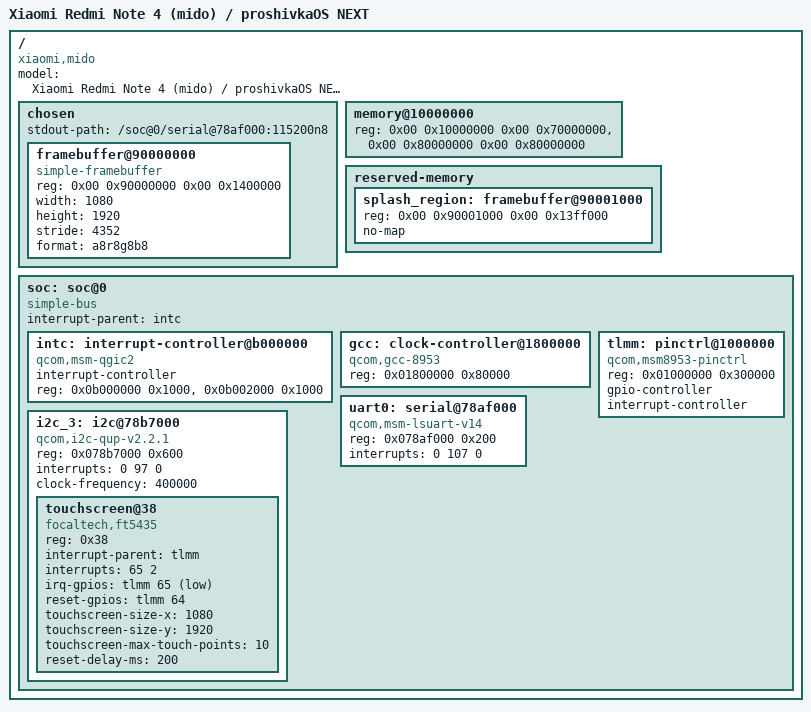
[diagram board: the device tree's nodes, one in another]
// SPDX-License-Identifier: GPL-2.0
/*
 * mido.dts — описание железа Xiaomi Redmi Note 4/4X (mido) для proshivkaOS NEXT.
 *
 * ЗАЧЕМ ЭТОТ ФАЙЛ, если система и так читает дерево от загрузчика.
 *
 * Загрузчик LK передаёт стоковое дерево Android — большое (около 400 КиБ) и
 * описывающее сотни узлов, из которых нам нужны четыре. Оно прекрасно
 * работает, и штатный путь именно такой. Но у него есть два пробела:
 *
 *   1. В нём нет узла simple-framebuffer. Это изобретение мейнлайна;
 *      Android-деревья вместо него описывают полноценный контроллер
 *      дисплея, который надо инициализировать самому. Наша система же
 *      пользуется тем, что загрузчик уже всё настроил, — и адрес готового
 *      буфера ей взять неоткуда.
 *   2. Узел тачскрина в стоковом дереве описан свойствами вендорского
 *      драйвера (focaltech,irq-gpio и подобными), а не общепринятыми
 *      именами.
 *
 * Поэтому здесь собрано минимальное дерево, содержащее ровно то, что читает
 * arch/arm64/platform.c. Его можно приделать к образу вместо стокового —
 * тогда система перестанет полагаться на запасные константы из mido.h.
 *
 * ОТКУДА ВЗЯТЫ ЗНАЧЕНИЯ. Все до единого сняты с работающего устройства
 * через adb, а не переписаны из чужих репозиториев:
 *
 *   model, compatible      /sys/firmware/devicetree/base/{model,compatible}
 *   память                 /proc/iomem, узел memory
 *   UART                   узел serial@78af000 + earlycon= в /proc/cmdline
 *   GIC                    узел interrupt-controller@b000000
 *   фреймбуфер             reserved-memory/splash_region@0x90001000
 *                          + /sys/class/graphics/fb0/{virtual_size,stride,bits_per_pixel}
 *   I2C                    узел i2c@78b7000 (qcom,clk-freq-in/out)
 *   тачскрин               узел focaltech@38
 *   TLMM                   узел pinctrl@1000000
 *
 * Сборка:
 *     dtc -I dts -O dtb -o mido.dtb arch/arm64/boards/mido.dts
 */

/dts-v1/;

/ {
	model = "Xiaomi Redmi Note 4 (mido) / proshivkaOS NEXT";
	compatible = "xiaomi,mido", "qcom,msm8953";

	#address-cells = <2>;
	#size-cells = <2>;

	chosen {
		/*
		 * Разрядности объявлены явно. Спецификация разрешает их не
		 * указывать, но тогда значения берутся по умолчанию (2 и 1), и
		 * длина reg у дочерних узлов начинает зависеть от того, чью
		 * трактовку применяет читающий: Linux (и мы вслед за ним) идёт
		 * вверх по дереву до первого объявления, а строгая проверка dtc
		 * подставляет умолчание. Явное объявление снимает вопрос.
		 */
		#address-cells = <2>;
		#size-cells = <2>;

		/*
		 * Отладочная консоль. Порт физически выведен на разъём
		 * наушников и требует кабеля с делителем напряжения.
		 *
		 * Именно stdout-path сообщает, КАКОЙ из двух портов является
		 * консолью: второй, uart@78b0000, уходит на модуль Bluetooth,
		 * и печатать отладку в него бессмысленно.
		 */
		stdout-path = "/soc@0/serial@78af000:115200n8";

		/*
		 * Экран, оставленный загрузчиком.
		 *
		 * Инициализировать дисплей не нужно: LK уже настроил тракт,
		 * чтобы показать свой логотип, и оставил его работающим. Ядро
		 * Linux на этом аппарате подтверждает это при старте строками
		 * "bootloader display is on" и "Continuous splash enabled".
		 *
		 * Шаг строки 4352 байта, а не 1080 * 4 = 4320: контроллер
		 * дисплея выравнивает строку до 1088 пикселей. Значение снято
		 * с /sys/class/graphics/fb0/stride работающего устройства.
		 */
		/*
		 * АДРЕС ЗАВИСИТ ОТ ЗАГРУЗЧИКА, и это не мелочь.
		 *
		 * Стоковый загрузчик Xiaomi отдаёт кадр с 0x90001000: первая
		 * страница по 0x90000000 занята данными DFPS (динамическая
		 * частота обновления), что видно по разметке стокового дерева —
		 * там рядом лежат dfps_data_mem@90000000 на 4 КиБ и
		 * splash_region@0x90001000.
		 *
		 * lk2nd этой страницы не резервирует и кладёт кадр прямо с
		 * MIPI_FB_ADDR (target/msm8953/include/target/display.h:69,
		 * значение 0x90000000). Дерево из этого файла приделывается
		 * именно к образу для lk2nd, поэтому здесь его значение;
		 * запасная константа для стокового пути осталась в mido.h.
		 *
		 * Ошибка в один этот адрес не фатальна и хорошо узнаваема:
		 * страница в 4096 байт — это неполная строка кадра, картинка
		 * поедет по вертикали примерно на один пиксель. Система при
		 * этом напечатает в журнал, каким адресом воспользовалась.
		 */
		framebuffer@90000000 {
			compatible = "simple-framebuffer";
			reg = <0x00 0x90000000 0x00 0x1400000>;
			width = <1080>;
			height = <1920>;
			stride = <4352>;
			format = "a8r8g8b8";
			status = "okay";
		};
	};

	/*
	 * Оперативная память: два банка, суммарно 3.75 ГиБ.
	 * Из /proc/iomem: System RAM с 0x10000000, второй банк с 0x80000000.
	 */
	memory@10000000 {
		device_type = "memory";
		reg = <0x00 0x10000000 0x00 0x70000000>,
		      <0x00 0x80000000 0x00 0x80000000>;
	};

	reserved-memory {
		#address-cells = <2>;
		#size-cells = <2>;
		ranges;

		/*
		 * Буфер, в котором лежит логотип загрузчика. Помечен как
		 * занятый, чтобы никто не разместил здесь ничего своего:
		 * контроллер дисплея продолжает читать отсюда кадр.
		 */
		splash_region: framebuffer@90001000 {
			reg = <0x00 0x90001000 0x00 0x13ff000>;
			no-map;
		};
	};

	soc: soc@0 {
		#address-cells = <1>;
		#size-cells = <1>;
		ranges = <0 0 0 0xffffffff>;
		compatible = "simple-bus";

		/* Кому адресованы номера прерываний во всех узлах ниже. Сами
		   прерывания пока не используются — обработчиков в системе нет,
		   вся периферия опрашивается в цикле, — но объявить владельца
		   всё равно надо: без этого номера ни к чему не привязаны, и
		   dtc справедливо ругается. */
		interrupt-parent = <&intc>;

		/*
		 * Разрядность адресов внутри этой шины — ОДНО слово, тогда как
		 * в корне их два. Это не мелочь: система обязана отследить
		 * смену при разборе дерева, иначе прочитает reg дочерних узлов
		 * неверно. См. стек разрядностей в arch/arm64/fdt.c.
		 */

		/* Контроллер прерываний. Пока только обнаруживается: в системе
		 * нет обработчиков, вся периферия опрашивается в цикле. */
		intc: interrupt-controller@b000000 {
			compatible = "qcom,msm-qgic2";
			interrupt-controller;
			#interrupt-cells = <3>;
			reg = <0x0b000000 0x1000>,   /* распределитель */
			      <0x0b002000 0x1000>;   /* интерфейс ядра */
		};

		/* Тактирование периферии. Шину I2C тачскрина приходится
		 * включать самостоятельно: загрузчик ей не пользуется. */
		gcc: clock-controller@1800000 {
			compatible = "qcom,gcc-8953";
			reg = <0x01800000 0x80000>;
			#clock-cells = <1>;
		};

		/* Контроллер выводов. У каждого вывода свой блок регистров
		 * размером 4 КиБ; отсюда размер 0x300000 на 768 выводов. */
		tlmm: pinctrl@1000000 {
			compatible = "qcom,msm8953-pinctrl";
			reg = <0x01000000 0x300000>;
			gpio-controller;
			#gpio-cells = <2>;
			interrupt-controller;
			#interrupt-cells = <2>;
		};

		/* Отладочная консоль. Блок UARTDM версии 1.4. */
		uart0: serial@78af000 {
			compatible = "qcom,msm-lsuart-v14";
			reg = <0x078af000 0x200>;
			interrupts = <0 107 0>;
			status = "okay";
		};

		/*
		 * Шина I2C тачскрина (BLSP1 QUP3).
		 *
		 * clock-frequency 400 кГц — режим fast, как в стоковом дереве
		 * (qcom,clk-freq-out). Сам блок тактуется от опорного кварца
		 * 19.2 МГц напрямую, без делителя: подтверждено через
		 * /sys/kernel/debug/clk — parent blsp1_qup3_i2c_apps_clk_src,
		 * исток xo_clk_src, rate 19200000.
		 */
		i2c_3: i2c@78b7000 {
			compatible = "qcom,i2c-qup-v2.2.1", "qcom,i2c-msm-v2";
			reg = <0x078b7000 0x600>;
			interrupts = <0 97 0>;
			clock-frequency = <400000>;
			#address-cells = <1>;
			#size-cells = <0>;
			status = "okay";

			/*
			 * Тачскрин FocalTech FT5435.
			 *
			 * На этой плате завод ставил контроллеры четырёх разных
			 * производителей (в стоковом дереве описаны также
			 * goodix_ts@14, imagis@50 и synaptics@4b). Установлен
			 * ровно один; в проверенном экземпляре, по
			 * /proc/bus/input/devices, работает ft5435_ts на 3-0038.
			 *
			 * Координаты контроллер отдаёт СРАЗУ В ПИКСЕЛЯХ панели,
			 * 0..1079 и 0..1919, — масштабировать их не нужно, в
			 * отличие от virtio-tablet в эмуляторе с его условной
			 * сеткой 0..32767.
			 */
			touchscreen@38 {
				compatible = "focaltech,ft5435", "edt,edt-ft5406";
				reg = <0x38>;

				/* Линия прерывания активна низким уровнем.
				 * Как прерывание не используется — обработчиков
				 * в системе нет, — но в опросном режиме она
				 * показывает, есть ли новые данные, и позволяет
				 * не занимать шину впустую. */
				interrupt-parent = <&tlmm>;
				interrupts = <65 2>;          /* по спаду */
				irq-gpios = <&tlmm 65 1>;     /* активен низким  */

				/* Сброс обязателен: загрузчик оставляет
				 * микросхему в неопределённом состоянии, а
				 * иногда и в спящем, из которого она не
				 * отвечает по I2C вовсе. */
				reset-gpios = <&tlmm 64 0>;

				touchscreen-size-x = <1080>;
				touchscreen-size-y = <1920>;
				touchscreen-max-touch-points = <10>;

				/* Задержки из стокового дерева:
				 * focaltech,hard-reset-delay-ms = 200 */
				reset-delay-ms = <200>;
			};
		};
	};
};
